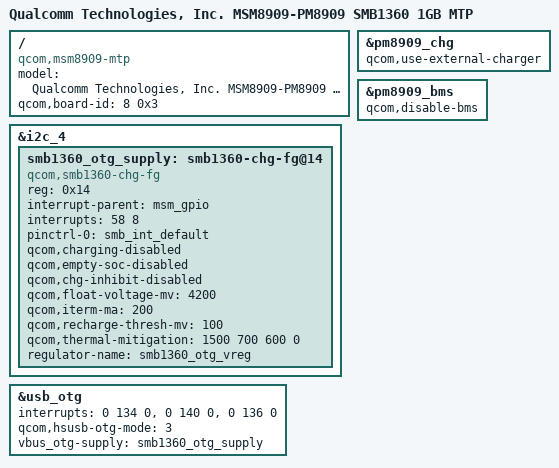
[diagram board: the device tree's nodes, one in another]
/* Copyright (c) 2014, The Linux Foundation. All rights reserved.
*
* This program is free software; you can redistribute it and/or modify
* it under the terms of the GNU General Public License version 2 and
* only version 2 as published by the Free Software Foundation.
*
* This program is distributed in the hope that it will be useful,
* but WITHOUT ANY WARRANTY; without even the implied warranty of
* MERCHANTABILITY or FITNESS FOR A PARTICULAR PURPOSE.  See the
* GNU General Public License for more details.
*/

/dts-v1/;

#include "msm8909-mtp.dtsi"
#include "msm8909-camera-sensor-mtp.dtsi"
#include "msm8909-pm8909.dtsi"
#include "msm8909-pm8909-mtp.dtsi"

/ {
	model = "Qualcomm Technologies, Inc. MSM8909-PM8909 SMB1360 1GB MTP";
	compatible = "qcom,msm8909-mtp", "qcom,msm8909", "qcom,mtp";
	qcom,board-id= <8 0x3>;
};

&i2c_4 {
	smb1360_otg_supply: smb1360-chg-fg@14 {
		compatible = "qcom,smb1360-chg-fg";
		reg = <0x14>;
		interrupt-parent = <&msm_gpio>;
		interrupts = <58 8>;
		pinctrl-names = "default";
		pinctrl-0 = <&smb_int_default>;
		qcom,charging-disabled;
		qcom,empty-soc-disabled;
		qcom,chg-inhibit-disabled;
		qcom,float-voltage-mv = <4200>;
		qcom,iterm-ma = <200>;
		qcom,recharge-thresh-mv = <100>;
		qcom,thermal-mitigation = <1500 700 600 0>;
		regulator-name = "smb1360_otg_vreg";
	};
};

&pm8909_chg {
	status = "ok";
	qcom,use-external-charger;
};

&pm8909_bms {
	status = "ok";
	qcom,disable-bms;
};

&usb_otg {
	interrupts = <0 134 0>,<0 140 0>,<0 136 0>;
	interrupt-names = "core_irq", "async_irq", "phy_irq";

	qcom,hsusb-otg-mode = <3>;
	vbus_otg-supply = <&smb1360_otg_supply>;
};
